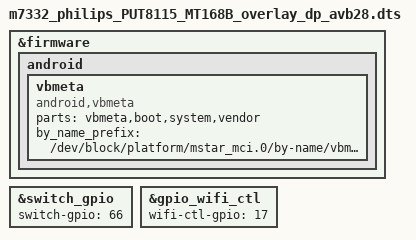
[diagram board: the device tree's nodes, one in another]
/dts-v1/;
/plugin/;

&firmware {
	android {
		vbmeta {
			compatible = "android,vbmeta";
			parts = "vbmeta,boot,system,vendor";
			by_name_prefix ="/dev/block/platform/mstar_mci.0/by-name/vbmeta";
		};
	};
};

&switch_gpio {
	switch-gpio = <66>;
};

&gpio_wifi_ctl {
	wifi-ctl-gpio = <17>;
};
